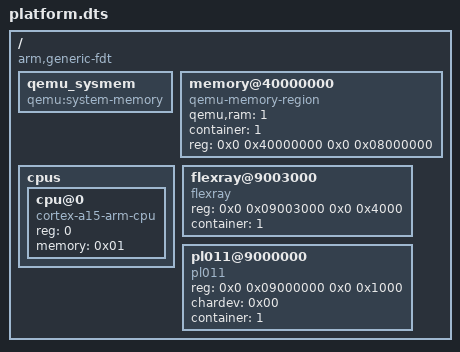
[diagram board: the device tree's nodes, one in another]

/dts-v1/;
/ {
    compatible = "arm,generic-fdt";
    #address-cells = <2>;
    #size-cells = <2>;
    qemu_sysmem: qemu_sysmem {
        compatible = "qemu:system-memory";
        phandle = <0x01>;
    };
    memory@40000000 {
        compatible = "qemu-memory-region";
        qemu,ram = <1>;
        container = <1>;
        reg = <0x0 0x40000000 0x0 0x08000000>;
    };
    cpus {
        #address-cells = <1>;
        #size-cells = <0>;
        cpu@0 {
            device_type = "cpu";
            compatible = "cortex-a15-arm-cpu";
            reg = <0>;
            memory = <0x01>;
        };
    };
    flexray@9003000 {
        compatible = "flexray";
        reg = <0x0 0x09003000 0x0 0x4000>;
        container = <1>;
    };
    pl011@9000000 {
        compatible = "pl011";
        reg = <0x0 0x09000000 0x0 0x1000>;
        chardev = <0x00>;
        container = <1>;
    };
};
